# RN831X_RN861X_MCU register map
File version: v0.0.1
CPU: RN831X_RN861X_MCU r1p0, little endian, MPU, no FPU
Registers are 32-bit, read-write, reset 0x0 unless marked. A register's access mark holds for its fields unless they carry their own. Offsets are from the block's base; [hi:lo] are bit positions; {n}, {i} and the like mark numbered series.

## GPIOA — GPIOA Module
Base 0xB0080000
Same registers: GPIOB 0xB0080400, GPIOC 0xB0080800, GPIOD 0xB0080C00, GPIOE 0xB0081000, GPIOF 0xB0081400, GPIOG 0xB0081800, GPIOH 0xB0081C00, GPIOL 0xB0082C00
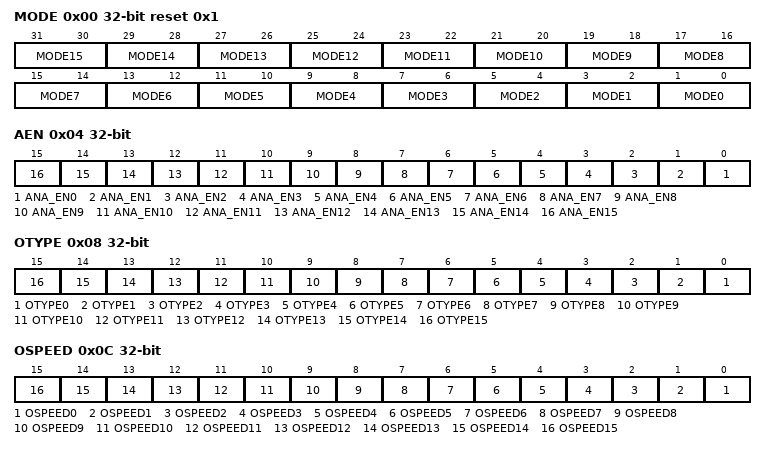
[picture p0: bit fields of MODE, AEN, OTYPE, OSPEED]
0x00 MODE reset 0x1 — GPIO mode register
  [all] fields
    0=INPUT (Input mode); 1=OUTPUT (Output mode); 2=ALTERNATE (Alternate funtion mode); 3=ANALOG (Analog mode)
  [2n+1:2n] MODE{n} (n=0..15) — mode control bits of Px{n:02}
0x04 AEN — Analog enable register
  [n] ANA_EN{n} (n=0..15) — Analog funtion enable bit of Px{n:02}
0x08 OTYPE — Output type register
  [all] fields
    0=NORMAL (normal output type); 1=OPENDRAIN (open-drain output type)
  [n] OTYPE{n} (n=0..15) — Output type control bit of Px{n:02}
0x0C OSPEED — Output speed register
  [all] fields
    0=NORMAL (Normal speed); 1=HIGHSPEED
  [n] OSPEED{n} (n=0..15) — output speed control bit of Px{n:02}
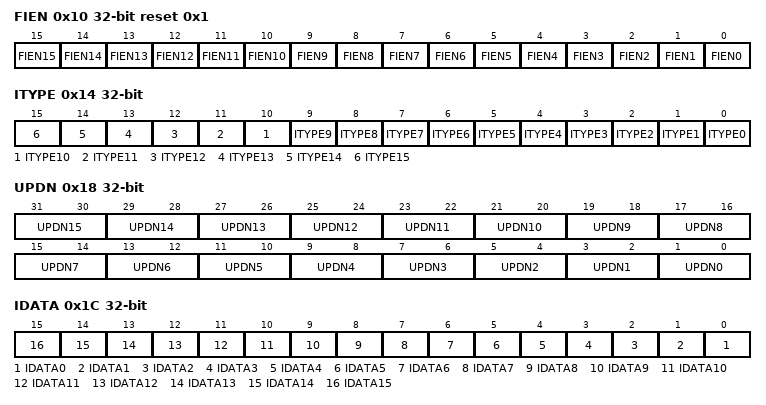
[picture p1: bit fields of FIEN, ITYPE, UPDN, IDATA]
0x10 FIEN reset 0x1 — Force input enable register
  [n] FIEN{n} (n=0..15) — Force input enable bit of Px{n:02}
0x14 ITYPE — Input type register
  [all] fields
    0=CMOS (CMOS buffer, Vil=0.3Vcc, Vih=0.7Vcc); 1=TTL (TTL buffer, Vil=0.16Vcc, Vih=0.4Vcc)
  [n] ITYPE{n} (n=0..15) — Input type control bit of Px{n:02}
0x18 UPDN — Pull up or pull down register
  [all] fields
    0=FLOATING (Select I/O no pull); 1=PULLUP (Select I/O pull up); 2=PULLDOWN (Select I/O pull down)
  [2n+1:2n] UPDN{n} (n=0..15) — Pull up/pull down control bits of Px{n:02}
0x1C IDATA read only — Input data
  [all] fields
    0=LOW (Low level); 1=HIGH (High level)
  [n] IDATA{n} (n=0..15) — Input data bit of Px{n:02}
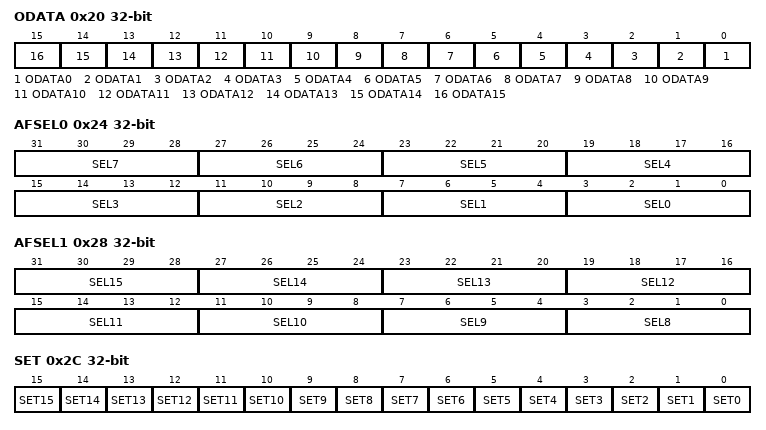
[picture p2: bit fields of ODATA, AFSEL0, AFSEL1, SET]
0x20 ODATA — Output data
  [all] fields
    0=LOW (Low level); 1=HIGH (High level)
  [n] ODATA{n} (n=0..15) — Output data of Px{n:02}
0x24 AFSEL0 — Alternate function seclect
  [all] fields
    {v}=AF{v} (Select alternate function {v}) (v=0..15)
  [4n+3:4n] SEL{n} (n=0..7) — Alternate function bits of Px{n:02}
0x28 AFSEL1 — Alternate function seclect
  [all] fields
    {v}=AF{v} (Select alternate function {v}) (v=0..15)
  [4n-29:4n-32] SEL{n} (n=8..15) — Alternate function bits of Px{n:02}
0x2C SET write only — Bit set
  [n] SET{n} (n=0..15) — Bit set of Px{n:02}
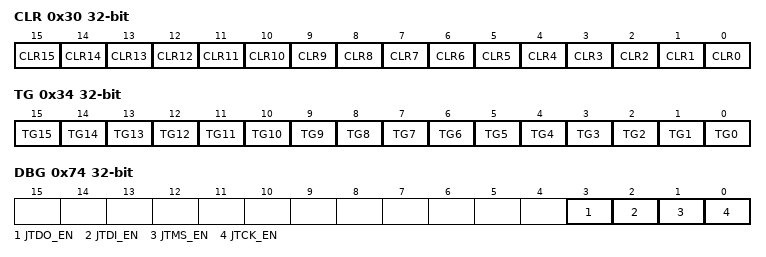
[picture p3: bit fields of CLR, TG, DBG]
0x30 CLR write only — Bit clear
  [n] CLR{n} (n=0..15) — Bit clear of Px{n:02}
0x34 TG write only — Bit toggle
  [n] TG{n} (n=0..15) — Bit toggle of Px{n:02}
0x70 DBG_KEY access not given — Key of debug register
  [31:0] KEY — Key of debug register bit
0x74 DBG — Debug register
  [3] JTDO_EN — enable bit of JTDO
  [2] JTDI_EN — enable bit of JTDI
  [1] JTMS_EN — enable bit of JTMS
  [0] JTCK_EN — enable bit of JTCK

## HSEM — HSEM Module
Base 0xB0084000
{0x0+4i} SEMAPHORE{i} access not given (i=0..31) — Hardware Semaphore Register {i}
  [9:0] SEMA_STATUS — Writing a non-0x3FF value indicates that a specific CORE get a semaphore

## I2C0_CORE0 — I2C0 Module core0
Base 0x20050000
Same registers: I2C1_CORE0 0x20054000, I2C0_CORE1 0xA0050000, I2C1_CORE1 0xA0054000
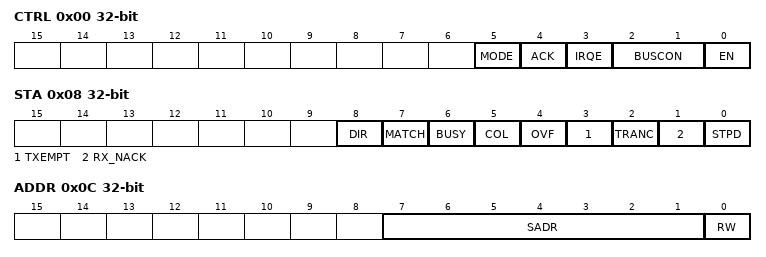
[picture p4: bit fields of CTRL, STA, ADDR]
0x00 CTRL — Control Register
  [5] MODE — Enable module
  [4] ACK — Bus control generate, start/stop condition generate
  [3] IRQE — Enable/disable interrupt
  [2:1] BUSCON — ACK Signal reception and transmission
    0=NONE (No Action); 1=START (Start Generation); 2=STOP (Stop Generation)
  [0] EN — Mode selection bit
0x04 CLK reset 0x1 — Clock Configuration Register
  [2:0] CLKDIV — Clock division parameter selection, set speed mode
    2=1M8_STANDARD_MODE (Standard mode in system clock 1.8432MHz, fast mode is not supported in this clock); 3=3M6_STANDARD_MODE (Standard mode in system clock 3.6864MHz, fast mode is not supported in this clock); 4=7M3_STANDARD_MODE (Standard mode in system clock 7.3728MHz); 2=7M3_FAST_MODE (Fast mode in system clock 7.3728MHz); 5=14M7_STANDARD_MODE (Standard mode in system clock 14.7456MHz); 3=14M7_FAST_MODE (Fast mode in system clock 14.7456MHz); 6=29M4_STANDARD_MODE (Standard mode in system clock 29.4912MHz); 4=29M4_FAST_MODE (Fast mode in system clock 29.4912MHz); 7=58M9_STANDARD_MODE (Standard mode in system clock 58.9824MHz); 5=58M9_FAST_MODE (Fast mode in system clock 58.9824MHz)
0x08 STA access per field — Status Indicator Register
  [8] DIR ro — Read/Write direction
  [7] MATCH ro — Address matching bit, will clear after detecting start/stop singal
  [6] BUSY ro — Communication status flag
  [5] COL rw write-1-clears — Transmi/receive conflict interrupt identifier bit (slave mode)
  [4] OVF rw write-1-clears — Receive overflow interrupt identifier bit (slave mode)
  [3] TXEMPT rw write-1-clears — Transmit data register empty error flag
  [2] TRANC rw write-1-clears — Transmission completion interrupt flag
  [1] RX_NACK rw write-1-clears — Received NACK interrupt flag
  [0] STPD rw write-1-clears — Stop signal detection interrupt flag
0x0C ADDR — Device Address Register
  [7:1] SADR — Device address, can not write during address transmission. Master mode, represents the slave device. Slave mode, use this address to compare with the address sent by master.
  [0] RW — Master read/write direction control bit
0x10 DATA access not given — Transceiver Register
  [7:0] TRDATA — Receive/send data. When host sends data, the cache should be empty before the data can be written
